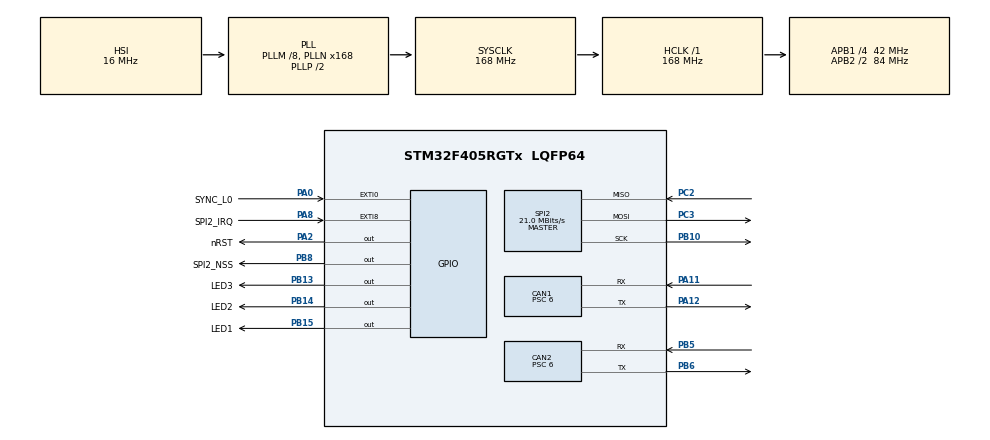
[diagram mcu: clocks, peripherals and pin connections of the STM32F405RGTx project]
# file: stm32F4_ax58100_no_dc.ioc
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CAN1.BS1=CAN_BS1_5TQ
CAN1.CalculateBaudRate=1000000
CAN1.CalculateTimeBit=1000
CAN1.CalculateTimeQuantum=142.85714285714286
CAN1.Prescaler=6
CAN2.BS1=CAN_BS1_3TQ
CAN2.BS2=CAN_BS2_3TQ
CAN2.CalculateBaudRate=1000000
CAN2.CalculateTimeBit=1000
CAN2.CalculateTimeQuantum=142.85714285714286
CAN2.Prescaler=6
Dma.Request0=SPI2_RX
Dma.Request1=SPI2_TX
Dma.SPI2_RX.0.Direction=DMA_PERIPH_TO_MEMORY
Dma.SPI2_RX.0.FIFOMode=DMA_FIFOMODE_DISABLE
Dma.SPI2_RX.0.Instance=DMA1_Stream3
Dma.SPI2_RX.0.MemDataAlignment=DMA_MDATAALIGN_BYTE
Dma.SPI2_RX.0.MemInc=DMA_MINC_ENABLE
Dma.SPI2_RX.0.Mode=DMA_NORMAL
Dma.SPI2_RX.0.PeriphDataAlignment=DMA_PDATAALIGN_BYTE
Dma.SPI2_RX.0.PeriphInc=DMA_PINC_DISABLE
Dma.SPI2_RX.0.Priority=DMA_PRIORITY_HIGH
Dma.SPI2_TX.1.Direction=DMA_MEMORY_TO_PERIPH
Dma.SPI2_TX.1.FIFOMode=DMA_FIFOMODE_DISABLE
Dma.SPI2_TX.1.Instance=DMA1_Stream4
Dma.SPI2_TX.1.MemDataAlignment=DMA_MDATAALIGN_BYTE
Dma.SPI2_TX.1.MemInc=DMA_MINC_ENABLE
Dma.SPI2_TX.1.Mode=DMA_NORMAL
Dma.SPI2_TX.1.PeriphDataAlignment=DMA_PDATAALIGN_BYTE
Dma.SPI2_TX.1.PeriphInc=DMA_PINC_DISABLE
Dma.SPI2_TX.1.Priority=DMA_PRIORITY_HIGH
Mcu.Family=STM32F4
Mcu.Name=STM32F405RGTx
Mcu.Package=LQFP64
NVIC.CAN1_RX0_IRQn=true\:0\:0\:false\:false\:true\:true\:true\:true
NVIC.CAN2_RX0_IRQn=true\:0\:0\:false\:false\:true\:true\:true\:true
NVIC.DMA1_Stream3_IRQn=true\:0\:0\:false\:false\:true\:true\:true\:true
NVIC.EXTI0_IRQn=true\:0\:0\:false\:false\:true\:true\:true\:true
NVIC.EXTI9_5_IRQn=true\:0\:0\:false\:false\:true\:true\:true\:true
NVIC.PriorityGroup=NVIC_PRIORITYGROUP_4
NVIC.TIM6_DAC_IRQn=true\:15\:0\:false\:false\:true\:false\:true\:true
NVIC.TimeBase=TIM6_DAC_IRQn
NVIC.TimeBaseIP=TIM6
PA0-WKUP.GPIO_Label=SYNC_L0
PA0-WKUP.Signal=GPXTI0
PA11.Mode=CAN_Activate
PA11.Signal=CAN1_RX
PA12.Mode=CAN_Activate
PA12.Signal=CAN1_TX
PA2.GPIO_Label=nRST
PA2.GPIO_PuPd=GPIO_PULLUP
PA2.Signal=GPIO_Output
PA8.GPIO_Label=SPI2_IRQ
PA8.Signal=GPXTI8
PB10.Mode=Full_Duplex_Master
PB10.Signal=SPI2_SCK
PB13.GPIO_Label=LED3
PB13.GPIO_PuPd=GPIO_PULLDOWN
PB13.Signal=GPIO_Output
PB14.GPIO_Label=LED2
PB14.GPIO_PuPd=GPIO_PULLDOWN
PB14.Signal=GPIO_Output
PB15.GPIO_Label=LED1
PB15.GPIO_PuPd=GPIO_PULLDOWN
PB15.Signal=GPIO_Output
PB5.Mode=CAN_Activate
PB5.Signal=CAN2_RX
PB6.Mode=CAN_Activate
PB6.Signal=CAN2_TX
PB8.GPIO_Label=SPI2_NSS
PB8.Signal=GPIO_Output
PC2.Mode=Full_Duplex_Master
PC2.Signal=SPI2_MISO
PC3.Mode=Full_Duplex_Master
PC3.Signal=SPI2_MOSI
PH0-OSC_IN.Mode=HSE-External-Oscillator
PH0-OSC_IN.Signal=RCC_OSC_IN
PH1-OSC_OUT.Mode=HSE-External-Oscillator
PH1-OSC_OUT.Signal=RCC_OSC_OUT
ProjectManager.HeapSize=0x200
ProjectManager.StackSize=0x400
ProjectManager.TargetToolchain=Makefile
RCC.48MHZClocksFreq_Value=48000000
RCC.AHBFreq_Value=168000000
RCC.APB1CLKDivider=RCC_HCLK_DIV4
RCC.APB1Freq_Value=42000000
RCC.APB1TimFreq_Value=84000000
RCC.APB2CLKDivider=RCC_HCLK_DIV2
RCC.APB2Freq_Value=84000000
RCC.APB2TimFreq_Value=168000000
RCC.CortexFreq_Value=168000000
RCC.HCLKFreq_Value=168000000
RCC.HSE_VALUE=8000000
RCC.HSI_VALUE=16000000
RCC.LSE_VALUE=32768
RCC.PLLM=8
RCC.PLLN=168
RCC.PLLQ=7
RCC.SYSCLKFreq_VALUE=168000000
RCC.SYSCLKSource=RCC_SYSCLKSOURCE_PLLCLK
RCC.VCOOutputFreq_Value=336000000
SPI2.BaudRatePrescaler=SPI_BAUDRATEPRESCALER_2
SPI2.CRCCalculation=SPI_CRCCALCULATION_ENABLE
SPI2.CRCPolynomial=X7
SPI2.CalculateBaudRate=21.0 MBits/s
SPI2.Direction=SPI_DIRECTION_2LINES
SPI2.Mode=SPI_MODE_MASTER
SPI2.VirtualType=VM_MASTER
VP_SYS_VS_tim6.Mode=TIM6
board=custom

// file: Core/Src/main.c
/* USER CODE BEGIN Header */
/**
 ******************************************************************************
 * @file           : main.c
 * @brief          : Main program body
 ******************************************************************************
 * @attention
 *
 * Copyright (c) 2023 STMicroelectronics.
 * All rights reserved.
 *
 * This software is licensed under terms that can be found in the LICENSE file
 * in the root directory of this software component.
 * If no LICENSE file comes with this software, it is provided AS-IS.
 *
 ******************************************************************************
 */
/* USER CODE END Header */
#include "main.h"

CAN_HandleTypeDef hcan1;
CAN_HandleTypeDef hcan2;

SPI_HandleTypeDef hspi2;
DMA_HandleTypeDef hdma_spi2_rx;
DMA_HandleTypeDef hdma_spi2_tx;

void SystemClock_Config(void);
static void MX_GPIO_Init(void);
static void MX_DMA_Init(void);
static void MX_CAN2_Init(void);
static void MX_CAN1_Init(void);
static void MX_SPI2_Init(void);
/* USER CODE BEGIN PFP */
int led_flag = 0;
/* USER CODE END PFP */

/* USER CODE BEGIN 0 */
void ecatapp_loop(void)
{
    led_flag == 1;
    //ecat_slv_poll();
    //DIG_process(DIG_PROCESS_WD_FLAG | DIG_PROCESS_OUTPUTS_FLAG |
    //     DIG_PROCESS_APP_HOOK_FLAG | DIG_PROCESS_INPUTS_FLAG);
}
/* USER CODE END 0 */

int main(void)
{

  /* MCU Configuration--------------------------------------------------------*/

  /* Reset of all peripherals, Initializes the Flash interface and the Systick. */
  HAL_Init();

  /* Configure the system clock */
  SystemClock_Config();

  /* Initialize all configured peripherals */
  MX_GPIO_Init();
  MX_DMA_Init();
  MX_CAN2_Init();
  MX_CAN1_Init();
  MX_SPI2_Init();
  /* USER CODE BEGIN 2 */
  //ecatapp_init();
  /* USER CODE END 2 */

  /* Infinite loop */
  while (1)
  {

    /* USER CODE BEGIN 3 */

    if (led_flag == 1)
    {
      HAL_GPIO_WritePin(LED2_GPIO_Port, LED2_Pin, GPIO_PIN_SET);
    }
    else
    {
      HAL_GPIO_WritePin(LED2_GPIO_Port, LED2_Pin, GPIO_PIN_RESET);
    }

    ecatapp_loop();
  }
  /* USER CODE END 3 */
}

void SystemClock_Config(void)
{
  RCC_OscInitTypeDef RCC_OscInitStruct = {0};
  RCC_ClkInitTypeDef RCC_ClkInitStruct = {0};

  /** Configure the main internal regulator output voltage
  */
  __HAL_RCC_PWR_CLK_ENABLE();
  __HAL_PWR_VOLTAGESCALING_CONFIG(PWR_REGULATOR_VOLTAGE_SCALE1);

  /** Initializes the RCC Oscillators according to the specified parameters
  * in the RCC_OscInitTypeDef structure.
  */
  RCC_OscInitStruct.OscillatorType = RCC_OSCILLATORTYPE_HSI;
  RCC_OscInitStruct.HSIState = RCC_HSI_ON;
  RCC_OscInitStruct.HSICalibrationValue = RCC_HSICALIBRATION_DEFAULT;
  RCC_OscInitStruct.PLL.PLLState = RCC_PLL_ON;
  RCC_OscInitStruct.PLL.PLLSource = RCC_PLLSOURCE_HSI;
  RCC_OscInitStruct.PLL.PLLM = 8;
  RCC_OscInitStruct.PLL.PLLN = 168;
  RCC_OscInitStruct.PLL.PLLP = RCC_PLLP_DIV2;
  RCC_OscInitStruct.PLL.PLLQ = 7;
  if (HAL_RCC_OscConfig(&RCC_OscInitStruct) != HAL_OK)
  {
    Error_Handler();
  }

  /** Initializes the CPU, AHB and APB buses clocks
  */
  RCC_ClkInitStruct.ClockType = RCC_CLOCKTYPE_HCLK|RCC_CLOCKTYPE_SYSCLK
                              |RCC_CLOCKTYPE_PCLK1|RCC_CLOCKTYPE_PCLK2;
  RCC_ClkInitStruct.SYSCLKSource = RCC_SYSCLKSOURCE_PLLCLK;
  RCC_ClkInitStruct.AHBCLKDivider = RCC_SYSCLK_DIV1;
  RCC_ClkInitStruct.APB1CLKDivider = RCC_HCLK_DIV4;
  RCC_ClkInitStruct.APB2CLKDivider = RCC_HCLK_DIV2;

  if (HAL_RCC_ClockConfig(&RCC_ClkInitStruct, FLASH_LATENCY_5) != HAL_OK)
  {
    Error_Handler();
  }
}

static void MX_CAN1_Init(void)
{

  hcan1.Instance = CAN1;
  hcan1.Init.Prescaler = 6;
  hcan1.Init.Mode = CAN_MODE_NORMAL;
  hcan1.Init.SyncJumpWidth = CAN_SJW_1TQ;
  hcan1.Init.TimeSeg1 = CAN_BS1_5TQ;
  hcan1.Init.TimeSeg2 = CAN_BS2_1TQ;
  hcan1.Init.TimeTriggeredMode = DISABLE;
  hcan1.Init.AutoBusOff = DISABLE;
  hcan1.Init.AutoWakeUp = DISABLE;
  hcan1.Init.AutoRetransmission = DISABLE;
  hcan1.Init.ReceiveFifoLocked = DISABLE;
  hcan1.Init.TransmitFifoPriority = DISABLE;
  if (HAL_CAN_Init(&hcan1) != HAL_OK)
  {
    Error_Handler();
  }

}

static void MX_CAN2_Init(void)
{

  hcan2.Instance = CAN2;
  hcan2.Init.Prescaler = 6;
  hcan2.Init.Mode = CAN_MODE_NORMAL;
  hcan2.Init.SyncJumpWidth = CAN_SJW_1TQ;
  hcan2.Init.TimeSeg1 = CAN_BS1_3TQ;
  hcan2.Init.TimeSeg2 = CAN_BS2_3TQ;
  hcan2.Init.TimeTriggeredMode = DISABLE;
  hcan2.Init.AutoBusOff = DISABLE;
  hcan2.Init.AutoWakeUp = DISABLE;
  hcan2.Init.AutoRetransmission = DISABLE;
  hcan2.Init.ReceiveFifoLocked = DISABLE;
  hcan2.Init.TransmitFifoPriority = DISABLE;
  if (HAL_CAN_Init(&hcan2) != HAL_OK)
  {
    Error_Handler();
  }

}

static void MX_SPI2_Init(void)
{

  /* SPI2 parameter configuration*/
  hspi2.Instance = SPI2;
  hspi2.Init.Mode = SPI_MODE_MASTER;
  hspi2.Init.Direction = SPI_DIRECTION_2LINES;
  hspi2.Init.DataSize = SPI_DATASIZE_8BIT;
  hspi2.Init.CLKPolarity = SPI_POLARITY_LOW;
  hspi2.Init.CLKPhase = SPI_PHASE_1EDGE;
  hspi2.Init.NSS = SPI_NSS_SOFT;
  hspi2.Init.BaudRatePrescaler = SPI_BAUDRATEPRESCALER_2;
  hspi2.Init.FirstBit = SPI_FIRSTBIT_MSB;
  hspi2.Init.TIMode = SPI_TIMODE_DISABLE;
  hspi2.Init.CRCCalculation = SPI_CRCCALCULATION_ENABLE;
  hspi2.Init.CRCPolynomial = 128;
  if (HAL_SPI_Init(&hspi2) != HAL_OK)
  {
    Error_Handler();
  }

}

static void MX_DMA_Init(void)
{

  /* DMA controller clock enable */
  __HAL_RCC_DMA1_CLK_ENABLE();

  /* DMA interrupt init */
  /* DMA1_Stream3_IRQn interrupt configuration */
  HAL_NVIC_SetPriority(DMA1_Stream3_IRQn, 0, 0);
  HAL_NVIC_EnableIRQ(DMA1_Stream3_IRQn);

}

static void MX_GPIO_Init(void)
{
  GPIO_InitTypeDef GPIO_InitStruct = {0};

  /* GPIO Ports Clock Enable */
  __HAL_RCC_GPIOH_CLK_ENABLE();
  __HAL_RCC_GPIOC_CLK_ENABLE();
  __HAL_RCC_GPIOA_CLK_ENABLE();
  __HAL_RCC_GPIOB_CLK_ENABLE();

  /*Configure GPIO pin Output Level */
  HAL_GPIO_WritePin(nRST_GPIO_Port, nRST_Pin, GPIO_PIN_RESET);

  /*Configure GPIO pin Output Level */
  HAL_GPIO_WritePin(GPIOB, LED3_Pin|LED2_Pin|LED1_Pin|SPI2_NSS_Pin, GPIO_PIN_RESET);

  /*Configure GPIO pins : SYNC_L0_Pin SPI2_IRQ_Pin */
  GPIO_InitStruct.Pin = SYNC_L0_Pin|SPI2_IRQ_Pin;
  GPIO_InitStruct.Mode = GPIO_MODE_IT_RISING;
  GPIO_InitStruct.Pull = GPIO_NOPULL;
  HAL_GPIO_Init(GPIOA, &GPIO_InitStruct);

  /*Configure GPIO pin : nRST_Pin */
  GPIO_InitStruct.Pin = nRST_Pin;
  GPIO_InitStruct.Mode = GPIO_MODE_OUTPUT_PP;
  GPIO_InitStruct.Pull = GPIO_PULLUP;
  GPIO_InitStruct.Speed = GPIO_SPEED_FREQ_LOW;
  HAL_GPIO_Init(nRST_GPIO_Port, &GPIO_InitStruct);

  /*Configure GPIO pins : LED3_Pin LED2_Pin LED1_Pin */
  GPIO_InitStruct.Pin = LED3_Pin|LED2_Pin|LED1_Pin;
  GPIO_InitStruct.Mode = GPIO_MODE_OUTPUT_PP;
  GPIO_InitStruct.Pull = GPIO_PULLDOWN;
  GPIO_InitStruct.Speed = GPIO_SPEED_FREQ_LOW;
  HAL_GPIO_Init(GPIOB, &GPIO_InitStruct);

  /*Configure GPIO pin : SPI2_NSS_Pin */
  GPIO_InitStruct.Pin = SPI2_NSS_Pin;
  GPIO_InitStruct.Mode = GPIO_MODE_OUTPUT_PP;
  GPIO_InitStruct.Pull = GPIO_NOPULL;
  GPIO_InitStruct.Speed = GPIO_SPEED_FREQ_LOW;
  HAL_GPIO_Init(SPI2_NSS_GPIO_Port, &GPIO_InitStruct);

  /* EXTI interrupt init*/
  HAL_NVIC_SetPriority(EXTI0_IRQn, 0, 0);
  HAL_NVIC_EnableIRQ(EXTI0_IRQn);

  HAL_NVIC_SetPriority(EXTI9_5_IRQn, 0, 0);
  HAL_NVIC_EnableIRQ(EXTI9_5_IRQn);

}

void HAL_TIM_PeriodElapsedCallback(TIM_HandleTypeDef *htim)
{
  if (htim->Instance == TIM6) {
    HAL_IncTick();
  }
}

void Error_Handler(void)
{
  __disable_irq();
  while (1)
  {
  }
}
